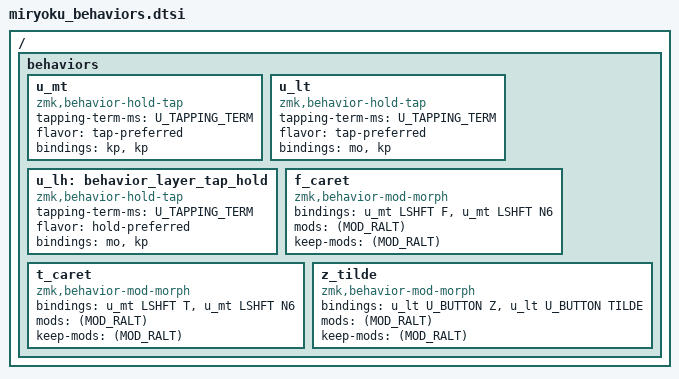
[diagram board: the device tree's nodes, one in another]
// Copyright 2022 Manna Harbour
// https://github.com/manna-harbour/miryoku

/ {
  behaviors {
    u_mt: u_mt {
      compatible = "zmk,behavior-hold-tap";
      #binding-cells = <2>;
      tapping-term-ms = <U_TAPPING_TERM>;
      flavor = "tap-preferred";
      bindings = <&kp>, <&kp>;
    };
    u_lt: u_lt {
      compatible = "zmk,behavior-hold-tap";
      #binding-cells = <2>;
      tapping-term-ms = <U_TAPPING_TERM>;
      flavor = "tap-preferred";
      bindings = <&mo>, <&kp>;
    };
    u_lh: behavior_layer_tap_hold {
      compatible = "zmk,behavior-hold-tap";
      #binding-cells = <2>;
      tapping-term-ms = <U_TAPPING_TERM>;
      flavor = "hold-preferred";
      bindings = <&mo>, <&kp>;
    };
    f_caret: f_caret {
      compatible = "zmk,behavior-mod-morph";
      #binding-cells = <0>;
      bindings = <&u_mt LSHFT F>, <&u_mt LSHFT N6>;
      mods = <(MOD_RALT)>;
      keep-mods = <(MOD_RALT)>;
    };
    t_caret: t_caret {
      compatible = "zmk,behavior-mod-morph";
      #binding-cells = <0>;
      bindings = <&u_mt LSHFT T>, <&u_mt LSHFT N6>;
      mods = <(MOD_RALT)>;
      keep-mods = <(MOD_RALT)>;
    };
    z_tilde: z_tilde {
      compatible = "zmk,behavior-mod-morph";
      #binding-cells = <0>;
      bindings = <&u_lt U_BUTTON Z>, <&u_lt U_BUTTON TILDE>;
      mods = <(MOD_RALT)>;
      keep-mods = <(MOD_RALT)>;
    };
  };
};
